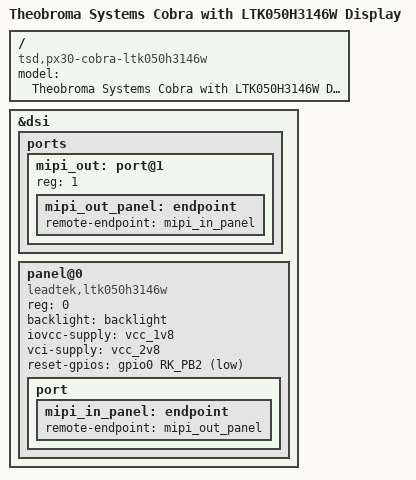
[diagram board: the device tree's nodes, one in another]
// SPDX-License-Identifier: (GPL-2.0+ OR MIT)
/*
 * Copyright (c) 2019 Theobroma Systems Design und Consulting GmbH
 */

/dts-v1/;
#include "px30-cobra.dtsi"

/ {
	model = "Theobroma Systems Cobra with LTK050H3146W Display";
	compatible = "tsd,px30-cobra-ltk050h3146w", "rockchip,px30-cobra", "rockchip,px30";
};

&dsi {
	status = "okay";

	ports {
		mipi_out: port@1 {
			reg = <1>;

			mipi_out_panel: endpoint {
				remote-endpoint = <&mipi_in_panel>;
			};
		};
	};

	panel@0 {
		compatible = "leadtek,ltk050h3146w";
		reg = <0>;
		backlight = <&backlight>;
		iovcc-supply = <&vcc_1v8>;
		vci-supply = <&vcc_2v8>;
		reset-gpios = <&gpio0 RK_PB2 GPIO_ACTIVE_LOW>;

		port {
			mipi_in_panel: endpoint {
				remote-endpoint = <&mipi_out_panel>;
			};
		};
	};
};
